# TMS320F280049 register map
Vendor: Texas Instruments; Series: C2000 F28004x; File version: 0.2.0-generated
Registers are 16-bit, read-write, reset 0x0 unless marked. A register's access mark holds for its fields unless they carry their own. Offsets are from the block's base; [hi:lo] are bit positions; {n}, {i} and the like mark numbered series; 'fields as' and 'values as' point back to an identical list.

## SDFM1REGS — SDFM Registers
Base 0x0000BC00
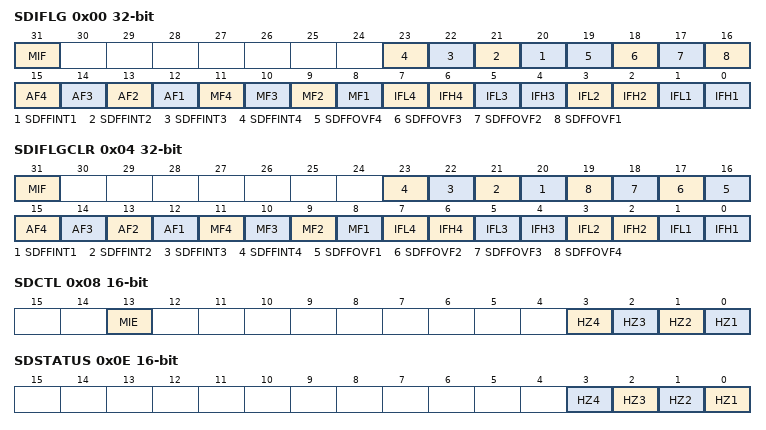
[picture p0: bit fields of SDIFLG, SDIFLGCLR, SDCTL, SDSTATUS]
0x00 SDIFLG 32-bit — SD Interrupt Flag Register
  [31] MIF — Master Interrupt Flag
  [n+19] SDFFINT{n} (n=1..4) — SDFIFO interrupt for Ch{n}
  [19] SDFFOVF4 — FIFO Overflow Flag for Ch4
  [18] SDFFOVF3 — FIFO Overflow Flag for Ch3
  [17] SDFFOVF2 — FIFO Overflow Flag for Ch2
  [16] SDFFOVF1 — FIFO Overflow Flag for Ch1.
  [n+11] AF{n} (n=1..4) — Acknowledge flag for Filter {n}
  [n+7] MF{n} (n=1..4) — Modulator Failure for Filter {n}
  [2n-1] IFL{n} (n=1..4) — Low-level Interrupt flag for Ch{n}
  [2n-2] IFH{n} (n=1..4) — High-level Interrupt flag for Ch{n}
0x04 SDIFLGCLR 32-bit — SD Interrupt Flag Clear Register
  [31] MIF — Master Interrupt Flag
  [n+19] SDFFINT{n} (n=1..4) — SDFIFO Interrupt flag-clear bit for Ch{n}
  [n+15] SDFFOVF{n} (n=1..4) — SDFIFO overflow clear Ch{n}
  [n+11] AF{n} (n=1..4) — Acknowledge flag for Filter {n}
  [n+7] MF{n} (n=1..4) — Modulator Failure for Filter {n}
  [2n-1] IFL{n} (n=1..4) — Low-level Interrupt flag for Ch{n}
  [2n-2] IFH{n} (n=1..4) — High-level Interrupt flag for Ch{n}
0x08 SDCTL — SD Control Register
  [13] MIE — Master SDy_ERR Interrupt enable
  [n-1] HZ{n} (n=1..4) — High-level Threshold crossing (Z) flag Ch{n}
0x0C SDMFILEN — SD Master Filter Enable
  [11] MFE — Master Filter Enable.
0x0E SDSTATUS
  [n-1] HZ{n} (n=1..4) — High-level Threshold crossing (Z) flag Ch{n}
{0x0+0x20*i} SDCTLPARM{i} (i=1..4) — Control Parameter Register for Ch{i}
  [2:1] MOD — Modulator clocking modes
{0x2+0x20*i} SDDFPARM{i} (i=1..4) — Data Filter Parameter Register for Ch{i}
  [12] SDSYNCEN — Data Filter Reset Enable
  [12:11] SST — Data filter Structure (SincFast/1/2/3)
  [9] AE — Ack Enable
  [8] FEN — Filter Enable
  [14:7] DOSR — Data Filter Oversample Ratio= DOSR+1
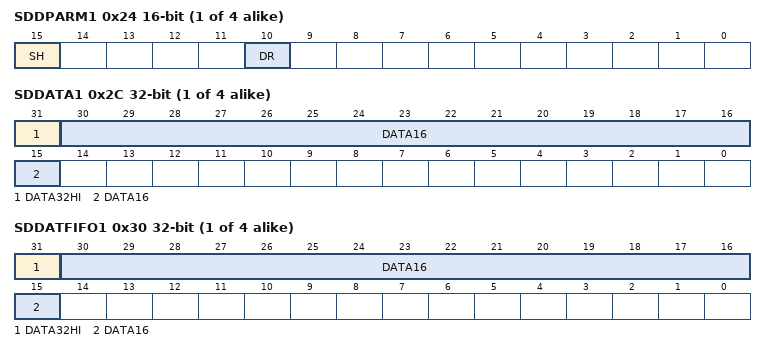
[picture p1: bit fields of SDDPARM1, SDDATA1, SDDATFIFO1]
{0x4+0x20*i} SDDPARM{i} (i=1..4) — Data Parameter Register for Ch{i}
  [15] SH — Shift Control (# bits to shift in 16b mode)
  [10] DR — Data Representation (0/1 = 16/32b 2's complement)
{0x6+0x20*i} SDCMPH{i} (i=1..4) — High-level Threshold Register for Ch{i}
  [15:14] HLT — High-level threshold for the comparator filter output
{0x8+0x20*i} SDCMPL{i} (i=1..4) — Low-level Threshold Register for Ch{i}
  [15:14] LLT — Low-level threshold for the comparator filter output
{0xA+0x20*i} SDCPARM{i} (i=1..4) — Comparator Filter Parameter Register for Ch{i}
  [13] CEN — Comparator Enable
  [10] HZEN — High level (Z) Threshold crossing output enable
  [9] MFIE — Modulator Failure Interrupt enable
  [9:8] CS1_CS0 — Comparator Filter Structure (SincFast/1/2/3)
  [6] IEL — Low-level interrupt enable
  [5] IEH — High-level Interrupt enable.
  [8:4] COSR — Comparator Oversample Ratio. Actual rate COSR+1
{0xC+0x20*i} SDDATA{i} 32-bit (i=1..4) — Data Filter Data Register (16 or 32bit) for Ch{i}
  [31] DATA32HI — Hi-order 16b in 32b mode, 16-bit Data in 16b mode
  [30:15] DATA16 — Lo-order 16b in 32b mode
{0x10+0x20*i} SDDATFIFO{i} 32-bit (i=1..4) — Filter Data FIFO Output(32b) for Ch{i}
  fields as SDDATA1
{0x14+0x20*i} SDCDATA{i} (i=1..4) — Comparator Filter Data Register (16b) for Ch{i}
  [15] DATA16 — Comparator Data output - 16b only
{0x18+0x20*i} SDCMPHZ{i} (i=1..4) — High-level (Z) Threshold Register for Ch{i}
  [15:14] HLTZ — High-level threshold (Z) for the comparator filter output
{0x1A+0x20*i} SDFIFOCTL{i} (i=1..4) — FIFO Control Register for Ch{i}
  [15] OVFIEN — SDFIFO Overflow interrupt enable
  [14] DRINTSEL — Data-Ready Interrupt Source Select
  [13] FFEN — SDFIFO Enable
  [12] FFIEN — SDFIFO data ready Interrupt Enable
  [14:10] SDFFST — SDFIFO Status
  [8:4] SDFFIL — SDFIFO Interrupt Level
{0x1C+0x20*i} SDSYNC{i} (i=1..4) — SD Filter Sync control for Ch{i}
  [10] WTSCLREN — WTSYNFLG Clear-on-FIFOINT Enable
  [9] FFSYNCCLREN — FIFO Clear-on-SDSYNC Enable
  [8] WTSYNCLR — Wait-for-Sync Flag Clear
  [7] WTSYNFLG — Wait-for-Sync Flag
  [6] WTSYNCEN — Wait-for-Sync Enable
  [10:5] SYNCSEL — SDSYNC Source Select
